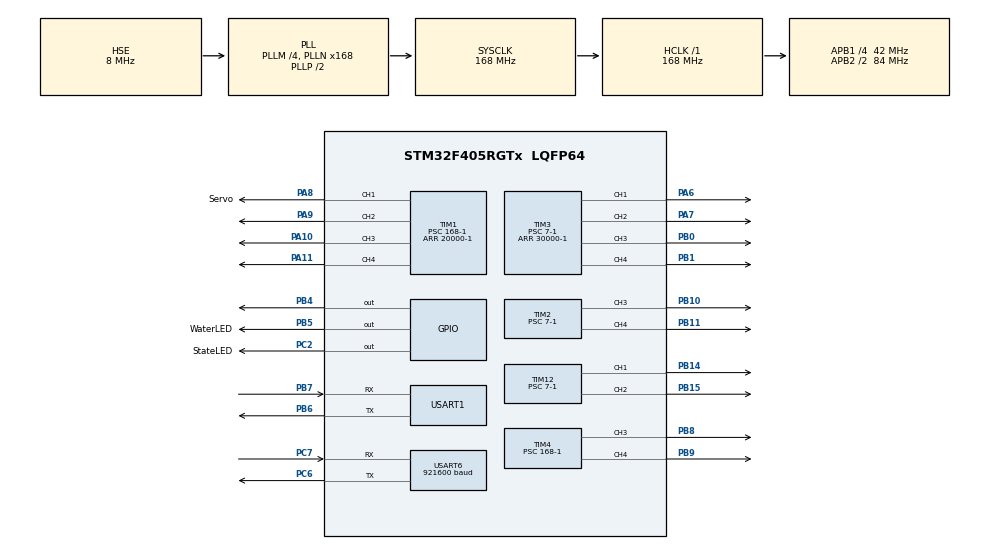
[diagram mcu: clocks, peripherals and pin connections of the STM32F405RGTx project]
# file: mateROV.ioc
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Dma.Request0=USART1_RX
Dma.Request1=USART6_RX
Dma.USART1_RX.0.Direction=DMA_PERIPH_TO_MEMORY
Dma.USART1_RX.0.FIFOMode=DMA_FIFOMODE_DISABLE
Dma.USART1_RX.0.Instance=DMA2_Stream2
Dma.USART1_RX.0.MemDataAlignment=DMA_MDATAALIGN_BYTE
Dma.USART1_RX.0.MemInc=DMA_MINC_ENABLE
Dma.USART1_RX.0.Mode=DMA_CIRCULAR
Dma.USART1_RX.0.PeriphDataAlignment=DMA_PDATAALIGN_BYTE
Dma.USART1_RX.0.PeriphInc=DMA_PINC_DISABLE
Dma.USART1_RX.0.Priority=DMA_PRIORITY_VERY_HIGH
Dma.USART6_RX.1.Direction=DMA_PERIPH_TO_MEMORY
Dma.USART6_RX.1.FIFOMode=DMA_FIFOMODE_DISABLE
Dma.USART6_RX.1.Instance=DMA2_Stream1
Dma.USART6_RX.1.MemDataAlignment=DMA_MDATAALIGN_BYTE
Dma.USART6_RX.1.MemInc=DMA_MINC_ENABLE
Dma.USART6_RX.1.Mode=DMA_CIRCULAR
Dma.USART6_RX.1.PeriphDataAlignment=DMA_PDATAALIGN_BYTE
Dma.USART6_RX.1.PeriphInc=DMA_PINC_DISABLE
Dma.USART6_RX.1.Priority=DMA_PRIORITY_LOW
FREERTOS.BinarySemaphores01=HI229BinarySem,Dynamic,NULL;RCBinarySem,Dynamic,NULL
FREERTOS.Tasks01=LEDTask,48,128,LEDTaskFun,As weak,NULL,Dynamic,NULL,NULL;HI229Task,40,128,HI229TaskFun,As weak,NULL,Dynamic,NULL,NULL;RCTask,55,128,RCTaskFun,As weak,NULL,Dynamic,NULL,NULL;RovTask,24,128,RovTaskFun,As weak,NULL,Dynamic,NULL,NULL
FREERTOS.configENABLE_FPU=1
FREERTOS.configTOTAL_HEAP_SIZE=15360
FREERTOS.configUSE_NEWLIB_REENTRANT=1
Mcu.Family=STM32F4
Mcu.Name=STM32F405RGTx
Mcu.Package=LQFP64
NVIC.DMA2_Stream1_IRQn=true\:5\:0\:false\:false\:true\:true\:false\:true\:true
NVIC.DMA2_Stream2_IRQn=true\:5\:0\:false\:false\:true\:true\:false\:true\:true
NVIC.PriorityGroup=NVIC_PRIORITYGROUP_4
NVIC.TIM5_IRQn=true\:15\:0\:false\:false\:true\:false\:false\:true\:true
NVIC.TimeBase=TIM5_IRQn
NVIC.TimeBaseIP=TIM5
NVIC.USART1_IRQn=true\:5\:0\:false\:false\:true\:true\:true\:true\:true
NVIC.USART6_IRQn=true\:5\:0\:false\:false\:true\:true\:true\:true\:true
PA10.Signal=S_TIM1_CH3
PA11.Signal=S_TIM1_CH4
PA13.Mode=Serial_Wire
PA13.Signal=SYS_JTMS-SWDIO
PA14.Mode=Serial_Wire
PA14.Signal=SYS_JTCK-SWCLK
PA6.Signal=S_TIM3_CH1
PA7.Signal=S_TIM3_CH2
PA8.GPIO_Label=Servo
PA8.Signal=S_TIM1_CH1
PA9.Signal=S_TIM1_CH2
PB0.Signal=S_TIM3_CH3
PB1.Signal=S_TIM3_CH4
PB10.Signal=S_TIM2_CH3
PB11.Signal=S_TIM2_CH4
PB14.Signal=S_TIM12_CH1
PB15.Signal=S_TIM12_CH2
PB4.Signal=GPIO_Output
PB5.GPIO_Label=WaterLED
PB5.Signal=GPIO_Output
PB6.Mode=Asynchronous
PB6.Signal=USART1_TX
PB7.Mode=Asynchronous
PB7.Signal=USART1_RX
PB8.Signal=S_TIM4_CH3
PB9.Signal=S_TIM4_CH4
PC2.GPIO_Label=StateLED
PC2.Signal=GPIO_Output
PC6.Mode=Asynchronous
PC6.Signal=USART6_TX
PC7.Mode=Asynchronous
PC7.Signal=USART6_RX
PH0-OSC_IN.Mode=HSE-External-Oscillator
PH0-OSC_IN.Signal=RCC_OSC_IN
PH1-OSC_OUT.Mode=HSE-External-Oscillator
PH1-OSC_OUT.Signal=RCC_OSC_OUT
ProjectManager.HeapSize=0x200
ProjectManager.StackSize=0x400
ProjectManager.TargetToolchain=STM32CubeIDE
RCC.48MHZClocksFreq_Value=84000000
RCC.AHBFreq_Value=168000000
RCC.APB1CLKDivider=RCC_HCLK_DIV4
RCC.APB1Freq_Value=42000000
RCC.APB1TimFreq_Value=84000000
RCC.APB2CLKDivider=RCC_HCLK_DIV2
RCC.APB2Freq_Value=84000000
RCC.APB2TimFreq_Value=168000000
RCC.CortexFreq_Value=168000000
RCC.HCLKFreq_Value=168000000
RCC.HSE_VALUE=8000000
RCC.HSI_VALUE=16000000
RCC.LSE_VALUE=32768
RCC.PLLM=4
RCC.PLLN=168
RCC.PLLSourceVirtual=RCC_PLLSOURCE_HSE
RCC.SYSCLKFreq_VALUE=168000000
RCC.SYSCLKSource=RCC_SYSCLKSOURCE_PLLCLK
RCC.VCOOutputFreq_Value=336000000
SH.S_TIM12_CH1.0=TIM12_CH1,PWM Generation1 CH1
SH.S_TIM12_CH2.0=TIM12_CH2,PWM Generation2 CH2
SH.S_TIM1_CH1.0=TIM1_CH1,PWM Generation1 CH1
SH.S_TIM1_CH2.0=TIM1_CH2,PWM Generation2 CH2
SH.S_TIM1_CH3.0=TIM1_CH3,PWM Generation3 CH3
SH.S_TIM1_CH4.0=TIM1_CH4,PWM Generation4 CH4
SH.S_TIM2_CH3.0=TIM2_CH3,PWM Generation3 CH3
SH.S_TIM2_CH4.0=TIM2_CH4,PWM Generation4 CH4
SH.S_TIM3_CH1.0=TIM3_CH1,PWM Generation1 CH1
SH.S_TIM3_CH2.0=TIM3_CH2,PWM Generation2 CH2
SH.S_TIM3_CH3.0=TIM3_CH3,PWM Generation3 CH3
SH.S_TIM3_CH4.0=TIM3_CH4,PWM Generation4 CH4
SH.S_TIM4_CH3.0=TIM4_CH3,PWM Generation3 CH3
SH.S_TIM4_CH4.0=TIM4_CH4,PWM Generation4 CH4
TIM1.Channel-PWM\ Generation1\ CH1=TIM_CHANNEL_1
TIM1.Channel-PWM\ Generation2\ CH2=TIM_CHANNEL_2
TIM1.Channel-PWM\ Generation3\ CH3=TIM_CHANNEL_3
TIM1.Channel-PWM\ Generation4\ CH4=TIM_CHANNEL_4
TIM1.OC1Preload_PWM=DISABLE
TIM1.OC2Preload_PWM=DISABLE
TIM1.OC3Preload_PWM=DISABLE
TIM1.OC4Preload_PWM=DISABLE
TIM1.Period=20000-1
TIM1.Prescaler=168-1
TIM1.Pulse-PWM\ Generation1\ CH1=1500
TIM1.Pulse-PWM\ Generation2\ CH2=930
TIM1.Pulse-PWM\ Generation3\ CH3=500
TIM1.Pulse-PWM\ Generation4\ CH4=2020
TIM12.Channel-PWM\ Generation1\ CH1=TIM_CHANNEL_1
TIM12.Channel-PWM\ Generation2\ CH2=TIM_CHANNEL_2
TIM12.OC1Preload_PWM=DISABLE
TIM12.OC2Preload_PWM=DISABLE
TIM12.Period=30000-1
TIM12.Prescaler=7-1
TIM12.Pulse-PWM\ Generation1\ CH1=2250
TIM12.Pulse-PWM\ Generation2\ CH2=2250
TIM2.Channel-PWM\ Generation3\ CH3=TIM_CHANNEL_3
TIM2.Channel-PWM\ Generation4\ CH4=TIM_CHANNEL_4
TIM2.OC3Preload_PWM=DISABLE
TIM2.OC4Preload_PWM=DISABLE
TIM2.Period=30000-1
TIM2.Prescaler=7-1
TIM2.Pulse-PWM\ Generation3\ CH3=2250
TIM2.Pulse-PWM\ Generation4\ CH4=2250
TIM3.Channel-PWM\ Generation1\ CH1=TIM_CHANNEL_1
TIM3.Channel-PWM\ Generation2\ CH2=TIM_CHANNEL_2
TIM3.Channel-PWM\ Generation3\ CH3=TIM_CHANNEL_3
TIM3.Channel-PWM\ Generation4\ CH4=TIM_CHANNEL_4
TIM3.OC1Preload_PWM=DISABLE
TIM3.OC2Preload_PWM=DISABLE
TIM3.OC3Preload_PWM=DISABLE
TIM3.OC4Preload_PWM=DISABLE
TIM3.Period=30000-1
TIM3.Prescaler=7-1
TIM3.Pulse-PWM\ Generation1\ CH1=2250
TIM3.Pulse-PWM\ Generation2\ CH2=2250
TIM3.Pulse-PWM\ Generation3\ CH3=2250
TIM3.Pulse-PWM\ Generation4\ CH4=2250
TIM4.Channel-PWM\ Generation3\ CH3=TIM_CHANNEL_3
TIM4.Channel-PWM\ Generation4\ CH4=TIM_CHANNEL_4
TIM4.OC3Preload_PWM=DISABLE
TIM4.OC4Preload_PWM=DISABLE
TIM4.Period=20000-1
TIM4.Prescaler=168-1
TIM4.Pulse-PWM\ Generation3\ CH3=800
TIM4.Pulse-PWM\ Generation4\ CH4=800
USART1.VirtualMode=VM_ASYNC
USART6.BaudRate=921600
USART6.VirtualMode=VM_ASYNC
VP_FREERTOS_VS_CMSIS_V2.Mode=CMSIS_V2
VP_SYS_VS_tim5.Mode=TIM5
VP_TIM1_VS_ClockSourceINT.Mode=Internal
VP_TIM2_VS_ClockSourceINT.Mode=Internal
VP_TIM3_VS_ClockSourceINT.Mode=Internal
board=custom

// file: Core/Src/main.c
/* USER CODE BEGIN Header */
/**
  ******************************************************************************
  * @file           : main.c
  * @brief          : Main program body
  ******************************************************************************
  * @attention
  *
  * Copyright (c) 2024 STMicroelectronics.
  * All rights reserved.
  *
  * This software is licensed under terms that can be found in the LICENSE file
  * in the root directory of this software component.
  * If no LICENSE file comes with this software, it is provided AS-IS.
  *
  ******************************************************************************
  */
/* USER CODE END Header */
#include "main.h"
#include "cmsis_os.h"
#include "dma.h"
#include "tim.h"
#include "usart.h"
#include "gpio.h"

void SystemClock_Config(void);
void MX_FREERTOS_Init(void);

int main(void)
{

  /* USER CODE BEGIN 1 */
    __HAL_RCC_HSI_ENABLE();
    __HAL_RCC_SYSCLK_CONFIG(RCC_SYSCLKSOURCE_HSI);
  /* USER CODE END 1 */

  /* MCU Configuration--------------------------------------------------------*/

  /* Reset of all peripherals, Initializes the Flash interface and the Systick. */
  HAL_Init();

  /* Configure the system clock */
  SystemClock_Config();

  /* Initialize all configured peripherals */
  MX_GPIO_Init();
  MX_DMA_Init();
  MX_TIM1_Init();
  MX_TIM2_Init();
  MX_TIM3_Init();
  MX_TIM12_Init();
  MX_TIM4_Init();
  MX_USART1_UART_Init();
  MX_USART6_UART_Init();

  /* Init scheduler */
  osKernelInitialize();

  /* Call init function for freertos objects (in cmsis_os2.c) */
  MX_FREERTOS_Init();

  /* Start scheduler */
  osKernelStart();

  /* We should never get here as control is now taken by the scheduler */

  /* Infinite loop */
  while (1)
  {

  }
}

void SystemClock_Config(void)
{
  RCC_OscInitTypeDef RCC_OscInitStruct = {0};
  RCC_ClkInitTypeDef RCC_ClkInitStruct = {0};

  /** Configure the main internal regulator output voltage
  */
  __HAL_RCC_PWR_CLK_ENABLE();
  __HAL_PWR_VOLTAGESCALING_CONFIG(PWR_REGULATOR_VOLTAGE_SCALE1);

  /** Initializes the RCC Oscillators according to the specified parameters
  * in the RCC_OscInitTypeDef structure.
  */
  RCC_OscInitStruct.OscillatorType = RCC_OSCILLATORTYPE_HSE;
  RCC_OscInitStruct.HSEState = RCC_HSE_ON;
  RCC_OscInitStruct.PLL.PLLState = RCC_PLL_ON;
  RCC_OscInitStruct.PLL.PLLSource = RCC_PLLSOURCE_HSE;
  RCC_OscInitStruct.PLL.PLLM = 4;
  RCC_OscInitStruct.PLL.PLLN = 168;
  RCC_OscInitStruct.PLL.PLLP = RCC_PLLP_DIV2;
  RCC_OscInitStruct.PLL.PLLQ = 4;
  if (HAL_RCC_OscConfig(&RCC_OscInitStruct) != HAL_OK)
  {
    Error_Handler();
  }

  /** Initializes the CPU, AHB and APB buses clocks
  */
  RCC_ClkInitStruct.ClockType = RCC_CLOCKTYPE_HCLK|RCC_CLOCKTYPE_SYSCLK
                              |RCC_CLOCKTYPE_PCLK1|RCC_CLOCKTYPE_PCLK2;
  RCC_ClkInitStruct.SYSCLKSource = RCC_SYSCLKSOURCE_PLLCLK;
  RCC_ClkInitStruct.AHBCLKDivider = RCC_SYSCLK_DIV1;
  RCC_ClkInitStruct.APB1CLKDivider = RCC_HCLK_DIV4;
  RCC_ClkInitStruct.APB2CLKDivider = RCC_HCLK_DIV2;

  if (HAL_RCC_ClockConfig(&RCC_ClkInitStruct, FLASH_LATENCY_5) != HAL_OK)
  {
    Error_Handler();
  }
}

void HAL_TIM_PeriodElapsedCallback(TIM_HandleTypeDef *htim)
{
  if (htim->Instance == TIM5) {
    HAL_IncTick();
  }
}

void Error_Handler(void)
{
  __disable_irq();
  while (1)
  {
  }
}

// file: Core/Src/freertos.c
/* USER CODE BEGIN Header */
/**
  ******************************************************************************
  * File Name          : freertos.c
  * Description        : Code for freertos applications
  ******************************************************************************
  * @attention
  *
  * Copyright (c) 2024 STMicroelectronics.
  * All rights reserved.
  *
  * This software is licensed under terms that can be found in the LICENSE file
  * in the root directory of this software component.
  * If no LICENSE file comes with this software, it is provided AS-IS.
  *
  ******************************************************************************
  */
/* USER CODE END Header */

#include "FreeRTOS.h"
#include "task.h"
#include "main.h"
#include "cmsis_os.h"

/* Definitions for LEDTask */
osThreadId_t LEDTaskHandle;
const osThreadAttr_t LEDTask_attributes = {
  .name = "LEDTask",
  .stack_size = 128 * 4,
  .priority = (osPriority_t) osPriorityRealtime,
};
/* Definitions for HI229Task */
osThreadId_t HI229TaskHandle;
const osThreadAttr_t HI229Task_attributes = {
  .name = "HI229Task",
  .stack_size = 128 * 4,
  .priority = (osPriority_t) osPriorityHigh,
};
/* Definitions for RCTask */
osThreadId_t RCTaskHandle;
const osThreadAttr_t RCTask_attributes = {
  .name = "RCTask",
  .stack_size = 128 * 4,
  .priority = (osPriority_t) osPriorityRealtime7,
};
/* Definitions for RovTask */
osThreadId_t RovTaskHandle;
const osThreadAttr_t RovTask_attributes = {
  .name = "RovTask",
  .stack_size = 128 * 4,
  .priority = (osPriority_t) osPriorityNormal,
};
/* Definitions for HI229BinarySem */
osSemaphoreId_t HI229BinarySemHandle;
const osSemaphoreAttr_t HI229BinarySem_attributes = {
  .name = "HI229BinarySem"
};
/* Definitions for RCBinarySem */
osSemaphoreId_t RCBinarySemHandle;
const osSemaphoreAttr_t RCBinarySem_attributes = {
  .name = "RCBinarySem"
};

void LEDTaskFun(void *argument);
void HI229TaskFun(void *argument);
void RCTaskFun(void *argument);
void RovTaskFun(void *argument);

void MX_FREERTOS_Init(void); /* (MISRA C 2004 rule 8.1) */

void MX_FREERTOS_Init(void) {

  /* Create the semaphores(s) */
  /* creation of HI229BinarySem */
  HI229BinarySemHandle = osSemaphoreNew(1, 0, &HI229BinarySem_attributes);

  /* creation of RCBinarySem */
  RCBinarySemHandle = osSemaphoreNew(1, 0, &RCBinarySem_attributes);

  /* Create the thread(s) */
  /* creation of LEDTask */
  LEDTaskHandle = osThreadNew(LEDTaskFun, NULL, &LEDTask_attributes);

  /* creation of HI229Task */
  HI229TaskHandle = osThreadNew(HI229TaskFun, NULL, &HI229Task_attributes);

  /* creation of RCTask */
  RCTaskHandle = osThreadNew(RCTaskFun, NULL, &RCTask_attributes);

  /* creation of RovTask */
  RovTaskHandle = osThreadNew(RovTaskFun, NULL, &RovTask_attributes);

}

__weak void LEDTaskFun(void *argument)
{
  for(;;)
  {
    osDelay(1);
  }
}

__weak void HI229TaskFun(void *argument)
{
  for(;;)
  {
    osDelay(1);
  }
}

__weak void RCTaskFun(void *argument)
{
  for(;;)
  {
    osDelay(1);
  }
}

__weak void RovTaskFun(void *argument)
{
  for(;;)
  {
    osDelay(1);
  }
}
